# CH32L103 register map
Vendor: WCH Ltd.; File version: 1.1
Registers are 32-bit, read-write, reset 0x0 unless marked. A register's access mark holds for its fields unless they carry their own. Offsets are from the block's base; [hi:lo] are bit positions; {n}, {i} and the like mark numbered series.

## PWR — Power control
Base 0x40007000
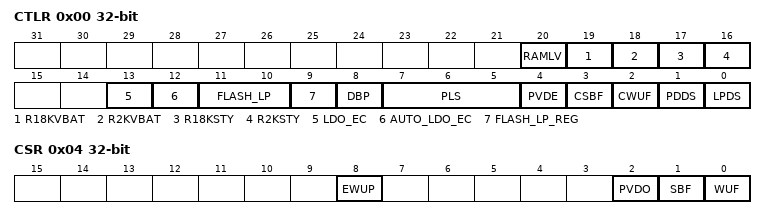
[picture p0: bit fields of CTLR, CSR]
0x00 CTLR — Power control register (PWR_CTRL)
  [20] RAMLV — Ram LV Enable
  [19] R18KVBAT — VBAT 18k ram enable
  [18] R2KVBAT — VBAT 2k ram enable
  [17] R18KSTY — standby 18k ram enable
  [16] R2KSTY — standby 2k ram enable
  [13] LDO_EC — LDO energy conservation mode enable
  [12] AUTO_LDO_EC — Auto energy conservation mode of LDO after entering stop mode
  [11:10] FLASH_LP — configuration FLASH status
  [9] FLASH_LP_REG — FLASH Low-power enable
  [8] DBP — Disable Backup Domain write protection
  [7:5] PLS — PVD Level Selection
  [4] PVDE — Power Voltage Detector Enable
  [3] CSBF — Clear STANDBY Flag
  [2] CWUF — Clear Wake-up Flag
  [1] PDDS — Power Down Deep Sleep
  [0] LPDS — Low Power Deep Sleep
0x04 CSR access per field — Power control register(PWR_CSR)
  [8] EWUP rw — Enable WKUP pin
  [2] PVDO ro — PVD Output
  [1] SBF ro — STANDBY Flag
  [0] WUF ro — Wake-Up Flag

## EXTEN — Exten configuration
Base 0x40023800
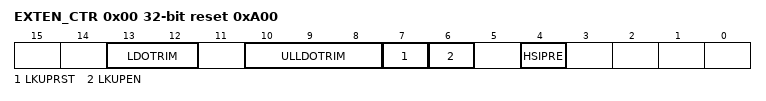
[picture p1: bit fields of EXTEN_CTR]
0x00 EXTEN_CTR access per field reset 0xA00 — EXTEN control register
  [13:12] LDOTRIM rw
  [10:8] ULLDOTRIM rw
  [7] LKUPRST read/clear — LOCKUP RESET
  [6] LKUPEN rw — LOCKUP_Eable
  [4] HSIPRE rw — Whether HSI is divided

## OPA — OPA configuration
Base 0x40026000
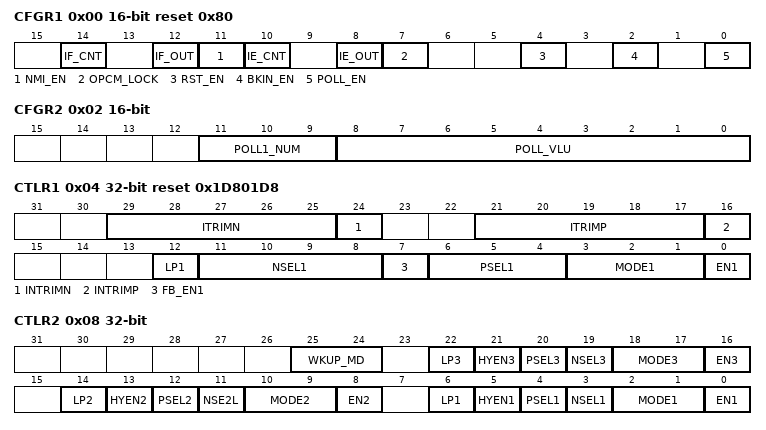
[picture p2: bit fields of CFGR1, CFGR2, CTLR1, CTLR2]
0x00 CFGR1 16-bit reset 0x80 — OPA configuration 1
  [14] IF_CNT — OPA interrupt flag at the end of polling interval
  [12] IF_OUT — OPA1 output interrupt
  [11] NMI_EN — OPA connection NMI interrupt enable
  [10] IE_CNT — OPA interrupt enable at the end of polling interval
  [8] IE_OUT — OPA1 interrupt enable
  [7] OPCM_LOCK — OPA and CMP LOCK
  [4] RST_EN — OPA1 reset enable
  [2] BKIN_EN — TIM1 brake input source selection
  [0] POLL_EN — OPA1 enable positive polling
0x02 CFGR2 16-bit — OPA configuration 2
  [11:9] POLL1_NUM — OPA1 polling the number of positive ends
  [8:0] POLL_VLU — OPA1 polling interval
0x04 CTLR1 reset 0x1D801D8 — OPA control register 1
  [29:25] ITRIMN — OPA1 low-level offset voltage value selection
  [24] INTRIMN — OPA1 low-level offset voltage value polarity selection
  [21:17] ITRIMP — OPA1 high-level offset voltage value selection
  [16] INTRIMP — OPA1 high-level offset voltage value polarity selection
  [12] LP1 — OPA1 low-power mode selection
  [11:8] NSEL1 — OPA1 negative end channel selection with PGA gain selection
  [7] FB_EN1 — OPA1 internal feedback resistance enable
  [6:4] PSEL1 — OPA1 forward input selection
  [3:1] MODE1 — OPA1 output channel selection
  [0] EN1 — OPA1 enable
0x08 CTLR2 — OPA control register 2
  [25:24] WKUP_MD — CMP wake-up signal mode selection
  [22] LP3 — CMP3 low-power switch
  [21] HYEN3 — CMP3 hysteresis function selection
  [20] PSEL3 — CMP3 forward input selection
  [19] NSEL3 — CMP3 negative input selection
  [18:17] MODE3 — CMP3 Output channel selection
  [16] EN3 — CMP3 enable
  [14] LP2 — CMP2 low-power switch
  [13] HYEN2 — CMP2 hysteresis function selection
  [12] PSEL2 — CMP2 forward input selection
  [11] NSE2L — CMP2 negative input selection
  [10:9] MODE2 — CMP2 Output channel selection
  [8] EN2 — CMP2 enable
  [6] LP1 — CMP1 low-power switch
  [5] HYEN1 — CMP1 hysteresis function selection
  [4] PSEL1 — CMP1 forward input selection
  [3] NSEL1 — CMP1 negative input selection
  [2:1] MODE1 — CMP1 Output channel selection
  [0] EN1 — CMP1 enable
0x14 OPCM_KEY — OPA and CMP unlockkey

## GPIOA — General purpose I/O
Base 0x40010800
Same registers: GPIOB 0x40010C00, GPIOC 0x40011000, GPIOD 0x40011400
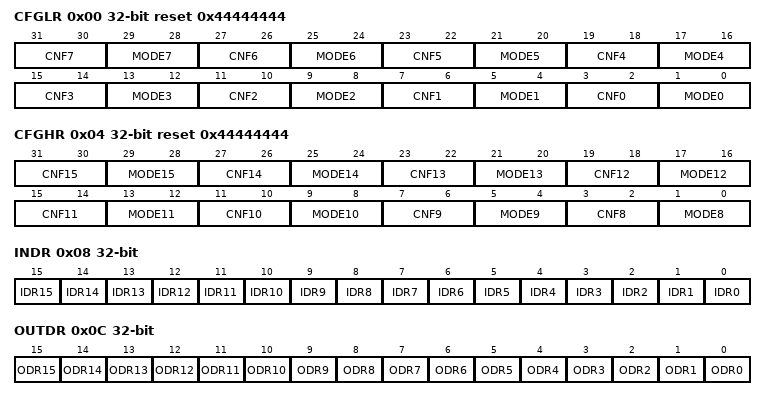
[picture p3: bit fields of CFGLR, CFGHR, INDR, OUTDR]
0x00 CFGLR reset 0x44444444 — Port configuration register low(GPIOn_CFGLR)
  [31:30] CNF7 — Port n.7 configuration bits
  [29:28] MODE7 — Port n.7 mode bits
  [27:26] CNF6 — Port n.6 configuration bits
  [25:24] MODE6 — Port n.6 mode bits
  [23:22] CNF5 — Port n.5 configuration bits
  [21:20] MODE5 — Port n.5 mode bits
  [19:18] CNF4 — Port n.4 configuration bits
  [17:16] MODE4 — Port n.4 mode bits
  [15:14] CNF3 — Port n.3 configuration bits
  [13:12] MODE3 — Port n.3 mode bits
  [11:10] CNF2 — Port n.2 configuration bits
  [9:8] MODE2 — Port n.2 mode bits
  [7:6] CNF1 — Port n.1 configuration bits
  [5:4] MODE1 — Port n.1 mode bits
  [3:2] CNF0 — Port n.0 configuration bits
  [1:0] MODE0 — Port n.0 mode bits
0x04 CFGHR reset 0x44444444 — Port configuration register high (GPIOn_CFGHR)
  [31:30] CNF15 — Port n.15 configuration bits
  [29:28] MODE15 — Port n.15 mode bits
  [27:26] CNF14 — Port n.14 configuration bits
  [25:24] MODE14 — Port n.14 mode bits
  [23:22] CNF13 — Port n.13 configuration bits
  [21:20] MODE13 — Port n.13 mode bits
  [19:18] CNF12 — Port n.12 configuration bits
  [17:16] MODE12 — Port n.12 mode bits
  [15:14] CNF11 — Port n.11 configuration bits
  [13:12] MODE11 — Port n.11 mode bits
  [11:10] CNF10 — Port n.10 configuration bits
  [9:8] MODE10 — Port n.10 mode bits
  [7:6] CNF9 — Port n.9 configuration bits
  [5:4] MODE9 — Port n.9 mode bits
  [3:2] CNF8 — Port n.8 configuration bits
  [1:0] MODE8 — Port n.8 mode bits
0x08 INDR ro — Port input data register (GPIOn_INDR)
  [n] IDR{n} (n=0..15) — Port input data
0x0C OUTDR — Port output data register (GPIOn_OUTDR)
  [n] ODR{n} (n=0..15) — Port output data
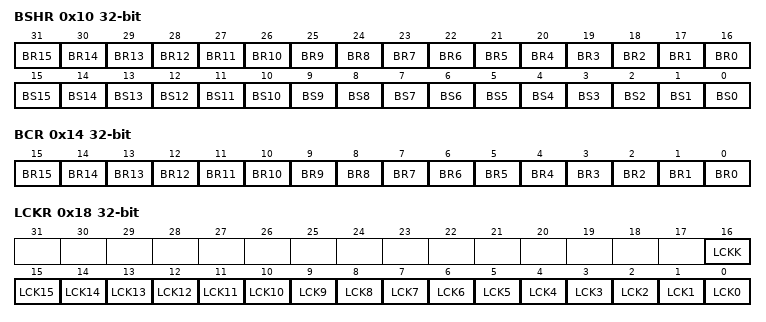
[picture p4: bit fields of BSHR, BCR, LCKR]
0x10 BSHR wo — Port bit set/reset register (GPIOn_BSHR)
  [n+16] BR{n} (n=0..15) — Reset bit {n}
  [n] BS{n} (n=3..15) — Set bit {n}
  [2] BS2 — Set bit 1
  [1] BS1 — Set bit 1
  [0] BS0 — Set bit 0
0x14 BCR wo — Port bit reset register (GPIOn_BCR)
  [n] BR{n} (n=3..15) — Reset bit {n}
  [2] BR2 — Reset bit 1
  [1] BR1 — Reset bit 1
  [0] BR0 — Reset bit 0
0x18 LCKR — Port configuration lock register
  [16] LCKK — Lock key
  [n] LCK{n} (n=0..15) — Port A Lock bit {n}
